# usbhs_reva_me18 register map
Registers are access not given, no defined reset value unless marked. A register's access mark holds for its fields unless they carry their own. Offsets are from the block's base; lines under a group give offsets from that group; [hi:lo] are bit positions; {n}, {i} and the like mark numbered series; 'fields as' and 'values as' point back to an identical list; <NAME> marks a mode.

## Memory map
0x400B1000 USBHS size 0x1000 — USB 2.0 High-speed Controller.

## Interrupts
2 USB (USBHS)

## USBHS — USB 2.0 High-speed Controller.
Base 0x400B1000
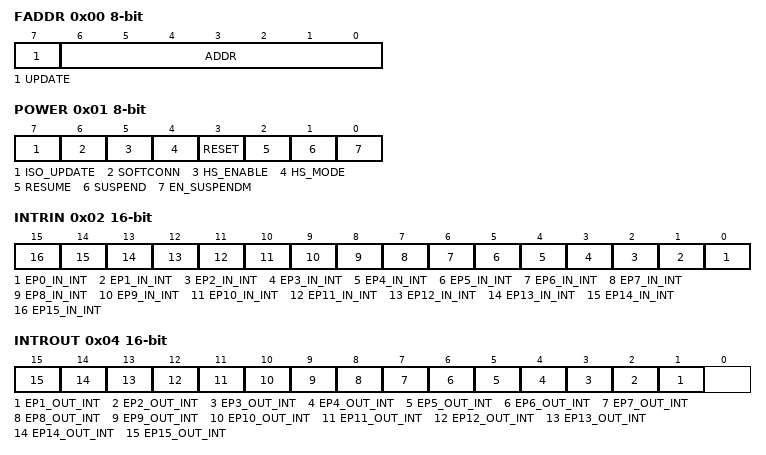
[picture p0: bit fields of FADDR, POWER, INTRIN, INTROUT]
0x00 FADDR 8-bit access per field — Function address register.
  [7] UPDATE ro — Set when ADDR is written, cleared when new address takes effect.
  [6:0] ADDR rw — Function address for this controller.
0x01 POWER 8-bit access per field — Power management register.
  [7] ISO_UPDATE rw — Wait for SOF during Isochronous xfers.
  [6] SOFTCONN rw
  [5] HS_ENABLE rw — High-speed mode enable.
  [4] HS_MODE ro — High-speed mode detected.
  [3] RESET ro — Bus reset detected.
  [2] RESUME rw — Generate resume signaling.
  [1] SUSPEND ro — Suspend mode detected.
  [0] EN_SUSPENDM rw — Enable SUSPENDM signal.
0x02 INTRIN 16-bit ro — Interrupt register for EP0 and IN EP1-15.
  [n] EP{n}_IN_INT (n=0..15) — Endpoint {n} interrupt.
0x04 INTROUT 16-bit ro — Interrupt register for OUT EP 1-15.
  [n] EP{n}_OUT_INT (n=1..15) — Endpoint {n} interrupt.
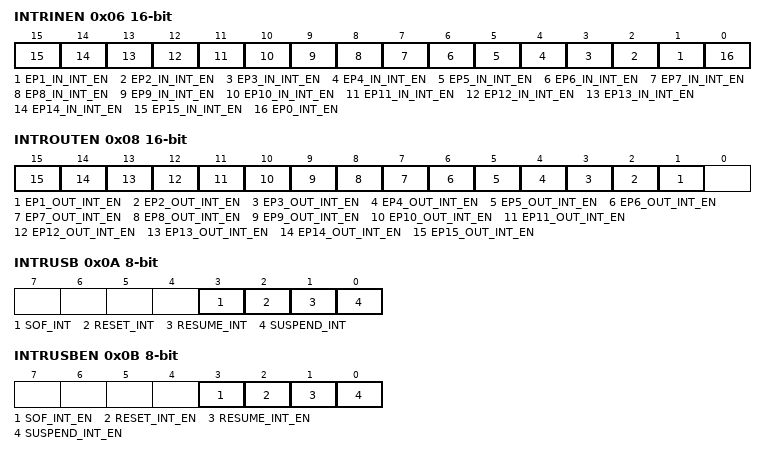
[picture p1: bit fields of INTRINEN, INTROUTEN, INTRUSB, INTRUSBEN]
0x06 INTRINEN 16-bit rw — Interrupt enable for EP 0 and IN EP 1-15.
  [n] EP{n}_IN_INT_EN (n=1..15) — Endpoint {n} interrupt enable.
  [0] EP0_INT_EN — Endpoint 0 interrupt enable.
0x08 INTROUTEN 16-bit rw — Interrupt enable for OUT EP 1-15.
  [n] EP{n}_OUT_INT_EN (n=1..15) — Endpoint {n} interrupt.
0x0A INTRUSB 8-bit ro — Interrupt register for common USB interrupts.
  [3] SOF_INT — Start of Frame.
  [2] RESET_INT — Bus reset detected.
  [1] RESUME_INT — Resume detected.
  [0] SUSPEND_INT — Suspend detected.
0x0B INTRUSBEN 8-bit rw — Interrupt enable for common USB interrupts.
  [3] SOF_INT_EN — Start of Frame.
  [2] RESET_INT_EN — Bus reset detected.
  [1] RESUME_INT_EN — Resume detected.
  [0] SUSPEND_INT_EN — Suspend detected.
0x0C FRAME 16-bit ro — Frame number.
  [10:0] FRAMENUM — Read the last received frame number, that is the 11-bit frame number received in the SOF packet.
0x0E INDEX 8-bit rw — Index for banked registers.
  [3:0] INDEX — Index Register Access Selector.
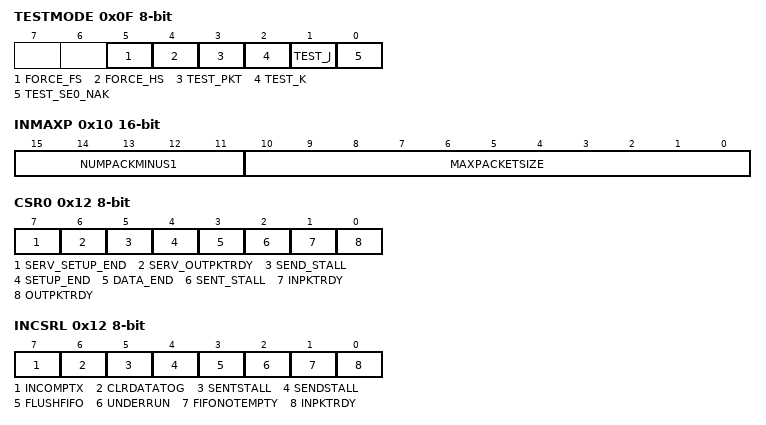
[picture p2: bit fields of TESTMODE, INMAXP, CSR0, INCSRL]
0x0F TESTMODE 8-bit rw — USB 2.0 test mode enable register.
  [5] FORCE_FS — Force USB to Full-speed after reset.
  [4] FORCE_HS — Force USB to High-speed after reset.
  [3] TEST_PKT — Transmit fixed test packet.
  [2] TEST_K — Force USB to continuous K state.
  [1] TEST_J — Force USB to continuous J state.
  [0] TEST_SE0_NAK — Respond to any valid IN token with NAK.
0x10 INMAXP 16-bit — Maximum packet size for INx endpoint (x == INDEX).
  [15:11] NUMPACKMINUS1 — Number of Split Packets - 1. Defines the maximum number of packets minus 1 that a USB payload can be split into. THis must be an exact multiple of maxpacketsize. Only applicable for HS High-Bandwidth isochronous endpoints and Bulk endpoints. Ignored in all other cases.
  [10:0] MAXPACKETSIZE — Maximum Packet Size in a Single Transaction. That is the maximum packet size in bytes, that is transmitted for each microframe. The maximum value is 1024, subject to the limitations of the endpoint type set in USB 2.0 Specification, Chapter 9
0x12 CSR0 8-bit access per field — Control status register for EP 0 (when INDEX == 0).
  [7] SERV_SETUP_END rw — Clear EP0 Setup End Bit. Write a 1 to clear the setupend bit. Automatically cleared after being set
  [6] SERV_OUTPKTRDY rw — Clear EP0 Out Packet Ready Bit. Write a 1 to clear the outpktrdy bit. Automatically cleared after being set.
  [5] SEND_STALL rw — Send EP0 STALL Handshake. Write a 1 to this bit to terminate the current control transaction by sneding a STALL handshake. Automatically cleared after being set.
  [4] SETUP_END ro — Read Setup End Status. Automatically set when a contorl transaction ends before the dataend bit has been set by fimrware. An interrupt is generated when this bit is set. Write 1 to servicedsetupend to clear.
  [3] DATA_END rw — Control Transaction Data End. Write a 1 to this bit after firmware completes any of the following three transactions: 1. set inpktrdy = 1 for the last data packet. 2. Set inpktrdy =1 for a zero-length data packet. 3. Clear outpktrdy = 0 after unloading the last data packet.
  [2] SENT_STALL rw — Read EP0 STALL Handshake Sent Status Automatically set when a STALL handshake is transmitted. Write a 0 to clear.
  [1] INPKTRDY rw — EP0 IN Packet Ready 1: Write a 1 after writing a data packet to the IN FIFO. Automatically cleared when the data packet is transmitted. An interrupt is generated when this bit is cleared.
  [0] OUTPKTRDY ro — EP0 OUT Packet Ready Status Automatically set when a data packet is received in the OUT FIFO. An interrupt is generated when this bit is set. Write a 1 to the servicedoutpktrdy bit (above) to clear after the packet is unloaded from the OUT FIFO.
0x12 INCSRL 8-bit access per field (alternate view of CSR0) — Control status lower register for INx endpoint (x == INDEX).
  [7] INCOMPTX rw — Read Incomplete Split Transfer Error Status High-bandwidth isochronous transfers: Automatically set when a payload is split into multiple packets but insufficient IN tokens were received to send all packets. The current packets is flushed from the IN FIFO. Write 0 to clear.
  [6] CLRDATATOG rw — Write 1 to clear IN endpoint data-toggle to 0.
  [5] SENTSTALL rw — Read STALL Handshake Sent Status Automatically set when a STALL handshake is transmitted, at which time the IN FIFO is flushed, and inpktrdy is cleared. Write 0 to clear.
  [4] SENDSTALL ro — Send STALL Handshake.
    0=Terminate STALL handhsake; 1=Respond to an IN token with a STALL handshake
  [3] FLUSHFIFO rw — Flush Next Packet from IN FIFO. Write 1 to clear
  [2] UNDERRUN rw — Read IN FIFO Underrun Error Status Isochronous Mode: Automatically set if the IN FIFO is empty. Write 0 to clear
  [1] FIFONOTEMPTY rw — Read FIFO Not Empty Status. Automatically set when there is at least one packet in the IN FIFO. Write a 0 to clear.
  [0] INPKTRDY ro — IN Packet Ready. Write a 1 to clear
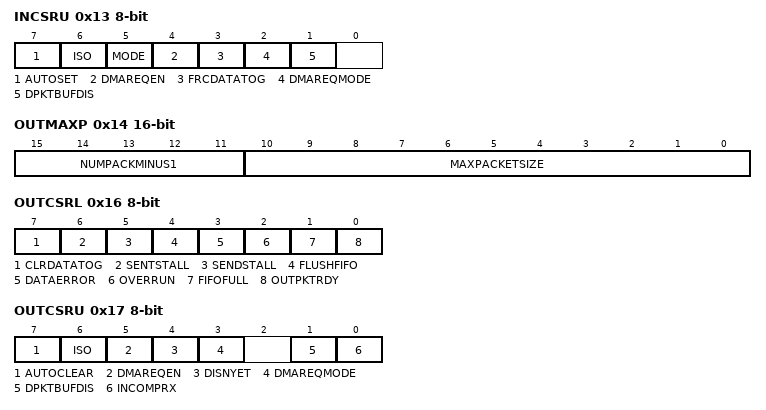
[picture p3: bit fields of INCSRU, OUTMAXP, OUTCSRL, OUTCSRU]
0x13 INCSRU 8-bit rw — Control status upper register for INx endpoint (x == INDEX).
  [7] AUTOSET — Auto Set inpktrdy.
    0=set (USBHS_INCSRL_inpktrdy must be set by firmware.); 1=auto (USBHS_INCSRL_inpktrdy is automatically set.)
  [6] ISO — Isochronous Transfer Enable
    0=interrupt (Enable IN Bulk and IN interrupt transfers.); 1=isochronous (Enable IN Isochronous transfers.)
  [5] MODE — Endpoint Direction Mode.
    0=out (Endpoint direction is OUT.); 1=in (Endpoint direction is IN.)
  [4] DMAREQEN — DMA Request Enable
    0=dis (Disable DMA for this IN endpoint.); 1=en (Enable DMA for this IN endpoint.)
  [3] FRCDATATOG — Force In Data - Toggle
    0=received (Toggle data-toglge only when an ACK is received.); 1=dontcare (Toggle data-toggle regardless of ACK.)
  [2] DMAREQMODE — DMA Request Mode Enable
    0=Enable DMA Request Mode 0; 1=Enable DMA Request Mode 1
  [1] DPKTBUFDIS — Double Packet Buffering Disable
    0=en (Enable Double packet buffering.); 1=dis (Disable Double Packet Buffering.)
0x14 OUTMAXP 16-bit — Maximum packet size for OUTx endpoint (x == INDEX).
  [15:11] NUMPACKMINUS1 — Number of Split Packets -1. Defines the maximum number of packets - 1 that a usb payload is combined into. The value must be exact multiple of maxpacketsize.
  [10:0] MAXPACKETSIZE — Maximum Packet in a Single Transaction. This is the maximum packet size, in bytes, that is transmitted for each microframe. The maximum value is 1024, subject to the limitations for the endpoint type set in USB2.0 spesification, chapter 9.
0x16 OUTCSRL 8-bit access per field — Control status lower register for OUTx endpoint (x == INDEX).
  [7] CLRDATATOG rw, [6] SENTSTALL rw, [5] SENDSTALL rw, [4] FLUSHFIFO rw, [3] DATAERROR ro, [2] OVERRUN rw, [1] FIFOFULL ro, [0] OUTPKTRDY rw
0x17 OUTCSRU 8-bit access per field — Control status upper register for OUTx endpoint (x == INDEX).
  [7] AUTOCLEAR rw, [6] ISO rw, [5] DMAREQEN rw, [4] DISNYET rw, [3] DMAREQMODE rw, [1] DPKTBUFDIS rw, [0] INCOMPRX ro
0x18 COUNT0 16-bit ro — Number of received bytes in EP 0 FIFO (INDEX == 0).
  [6:0] COUNT0 — Read Number of Data Bytes in the Endpoint 0 FIFO. Returns the number of data bytes in the endpoint 0 FIFO. This value changes as contents of the FIFO change. The value is only valued when USBHS_OUTSCRL_outpktrdy = 1
0x18 OUTCOUNT 16-bit ro (alternate view of COUNT0) — Number of received bytes in OUT EPx FIFO (x == INDEX).
  [12:0] OUTCOUNT — Read Number of Data Bytes in OUT FIFO. Returns the number of data bytes in the packet that are read next in the OUT FIFO.
{0x20+4i} FIFO{i} (i=0..15) — Read for OUT data FIFO, write for IN data FIFO.
  [31:0] USBHS_FIFO{i} — USBHS Endpoint FIFO Read/Write Register.
0x6C HWVERS 16-bit
  [15:0] USBHS_HWVERS — USBHS Register.
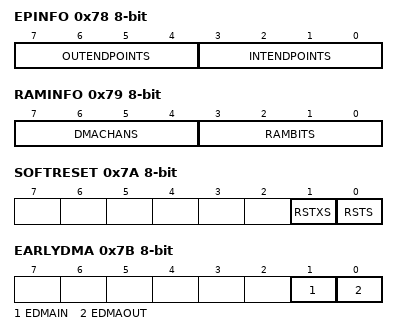
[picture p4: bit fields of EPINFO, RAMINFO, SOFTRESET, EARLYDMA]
0x78 EPINFO 8-bit ro — Endpoint hardware information.
  [7:4] OUTENDPOINTS, [3:0] INTENDPOINTS
0x79 RAMINFO 8-bit ro — RAM width and DMA hardware information.
  [7:4] DMACHANS, [3:0] RAMBITS
0x7A SOFTRESET 8-bit rw — Software reset register.
  [1] RSTXS, [0] RSTS
0x7B EARLYDMA 8-bit rw — DMA timing control register.
  [1] EDMAIN, [0] EDMAOUT
0x80 CTUCH 16-bit — Chirp timeout timer setting.
  [15:0] C_T_UCH — HS Chirp Timeout Clock Cycles. This configures the chirp timeout used by this device to negotiate a HS connection with a FS Host.
0x82 CTHSRTN 16-bit — Sets delay between HS resume to UTM normal operating mode.
  [15:0] C_T_HSTRN — High Speed Resume Delay Clock Cycles. This configures the delay from when the RESUME state on the bus ends, the when the USBHS resumes normal operation.
0x400 MXM_USB_REG_00
0x404 M31_PHY_UTMI_RESET
0x408 M31_PHY_UTMI_VCONTROL
0x40C M31_PHY_CLK_EN
0x410 M31_PHY_PONRST
0x414 M31_PHY_NONCRY_RSTB
0x418 M31_PHY_NONCRY_EN
0x420 M31_PHY_U2_COMPLIANCE_EN
0x424 M31_PHY_U2_COMPLIANCE_DAC_ADJ
0x428 M31_PHY_U2_COMPLIANCE_DAC_ADJ_EN
0x42C M31_PHY_CLK_RDY
0x430 M31_PHY_PLL_EN
0x434 M31_PHY_BIST_OK
0x438 M31_PHY_DATA_OE
0x43C M31_PHY_OSCOUTEN
0x440 M31_PHY_LPM_ALIVE
0x444 M31_PHY_HS_BIST_MODE
0x448 M31_PHY_CORECLKIN
0x44C M31_PHY_XTLSEL
0x450 M31_PHY_LS_EN
0x454 M31_PHY_DEBUG_SEL
0x458 M31_PHY_DEBUG_OUT
0x45C M31_PHY_OUTCLKSEL
0x460 M31_PHY_XCFGI_31_0
0x464 M31_PHY_XCFGI_63_32
0x468 M31_PHY_XCFGI_95_64
0x46C M31_PHY_XCFGI_127_96
0x470 M31_PHY_XCFGI_137_128
0x474 M31_PHY_XCFGI_HS_COURSE_TUNE_NUM
0x478 M31_PHY_XCFGI_HS_FINE_TUNE_NUM
0x47C M31_PHY_XCFGI_FS_COURSE_TUNE_NUM
0x480 M31_PHY_XCFGI_FS_FINE_TUNE_NUM
0x484 M31_PHY_XCFGI_LOCK_RANGE_MAX
0x488 M31_PHY_XCFGI_LOCK_RANGE_MIN
0x48C M31_PHY_XCFGI_OB_RSEL
0x490 M31_PHY_XCFGI_OC_RSEL
0x494 M31_PHY_XCFGO
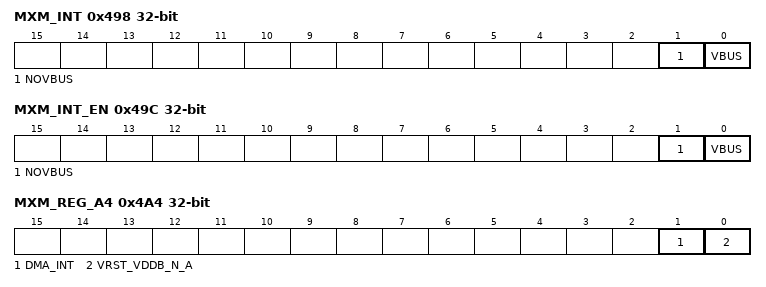
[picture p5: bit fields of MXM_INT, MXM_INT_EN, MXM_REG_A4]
0x498 MXM_INT — USB Added Maxim Interrupt Flag Register.
  [1] NOVBUS, [0] VBUS
0x49C MXM_INT_EN — USB Added Maxim Interrupt Enable Register.
  [1] NOVBUS, [0] VBUS
0x4A0 MXM_SUSPEND — USB Added Maxim Suspend Register.
  [0] SEL — Suspend register
0x4A4 MXM_REG_A4 — USB Added Maxim Power Status Register
  [1] DMA_INT, [0] VRST_VDDB_N_A
